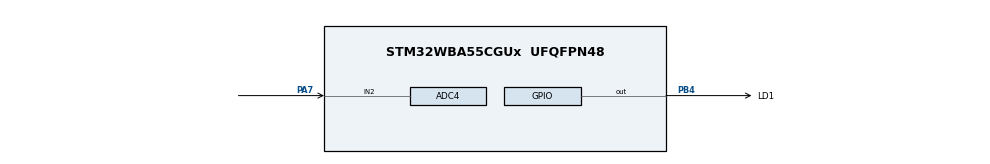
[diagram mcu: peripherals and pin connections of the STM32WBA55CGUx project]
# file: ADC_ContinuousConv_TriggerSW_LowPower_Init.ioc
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ADC4.Channel-0\#ChannelRegularConversion=ADC_CHANNEL_2
ADC4.ClockPrescaler=ADC_CLOCK_ASYNC_DIV4
ADC4.ContinuousConvMode=ENABLE
ADC4.LowPowerAutoPowerOff=DISABLE
ADC4.LowPowerAutoWait=ENABLE
ADC4.NbrOfConversionFlag=1
ADC4.Overrun=ADC_OVR_DATA_OVERWRITTEN
ADC4.Rank-0\#ChannelRegularConversion=1
ADC4.SamplingTime-0\#ChannelRegularConversion=ADC_SAMPLINGTIME_COMMON_1
ADC4.SamplingTimeCommon1=ADC_SAMPLETIME_79CYCLES_5
ADC4.SamplingTimeCommon2=ADC_SAMPLETIME_79CYCLES_5
ADC4.SelectedChannel=ADC_CHANNEL_2
CORTEX_M33_NS.userName=CORTEX_M33
Mcu.Family=STM32WBA
Mcu.Name=STM32WBA55CGUx
Mcu.Package=UFQFPN48
NVIC.PriorityGroup=NVIC_PRIORITYGROUP_4
OSC_IN.Mode=HSE-External-Oscillator
OSC_IN.Signal=RCC_OSC_IN
OSC_OUT.Mode=HSE-External-Oscillator
OSC_OUT.Signal=RCC_OSC_OUT
PA7.Mode=IN2
PA7.Signal=ADC4_IN2
PB4\ (NJTRST).GPIO_Label=LD1
PB4\ (NJTRST).PinState=GPIO_PIN_SET
PB4\ (NJTRST).Signal=GPIO_Output
ProjectManager.HeapSize=0x200
ProjectManager.StackSize=0x400
ProjectManager.TargetToolchain=EWARM V9.20
RCC.ADCCLockSelectionVirtual=RCC_ADCCLKSOURCE_HSI
RCC.ADCFreq_Value=16000000
RCC.AHB5CLKDivider=DIV4
RCC.AHBFreq_Value=100000000
RCC.APB1Freq_Value=100000000
RCC.APB1TimFreq_Value=100000000
RCC.APB2Freq_Value=100000000
RCC.APB2TimFreq_Value=100000000
RCC.CortexFreq_Value=12500000
RCC.HCLKFreq_Value=100000000
RCC.HSE_VALUE=32000000
RCC.HSI_VALUE=16000000
RCC.LSE_VALUE=32768
RCC.LSI1_VALUE=32000
RCC.LSI2_VALUE=32000
RCC.PLLM=4
RCC.PLLN=25
RCC.PLLSourceVirtual=RCC_PLLSOURCE_HSE
RCC.SYSCLKFreq_VALUE=100000000
RCC.SYSCLKSourceVirtual=RCC_SYSCLKSOURCE_PLLCLK
RCC.VCOOutputFreq_Value=200000000
VP_CORTEX_M33_NS_VS_Hclk.Mode=Hclk_Mode
VP_ICACHE_VS_ICACHE.Mode=DirectMappedCache
VP_MEMORYMAP_VS_MEMORYMAP.Mode=CurAppReg
VP_PWR_VS_SECSignals.Mode=Security/Privilege
board=custom

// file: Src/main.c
/* USER CODE BEGIN Header */
/**
  ******************************************************************************
  * @file    Examples_LL/ADC/ADC_ContinuousConv_TriggerSW_LowPower_Init/Src/main.c
  * @author  MCD Application Team
  * @brief   Use ADC to convert a single channel with ADC low power features
  *          auto wait and auto power-off: ADC conversions occurrences are
  *          limited to the minimum necessary to reduce power consumption
  *          and ADC is set automatically in mode disable during idle phase.

  *          These features are intended to be used by applications needing ADC
  *          conversions at few occurrences and without latency constraints.
  *          ADC low power features are used most commonly with programming
  *          model: polling.
  *          This example is based on the STM32WBAxx ADC LL API;
  *          Peripheral initialization done using LL unitary services functions.
  ******************************************************************************
  * @attention
  *
  * Copyright (c) 2023 STMicroelectronics.
  * All rights reserved.
  *
  * This software is licensed under terms that can be found in the LICENSE file
  * in the root directory of this software component.
  * If no LICENSE file comes with this software, it is provided AS-IS.
  *
  ******************************************************************************
  */
/* USER CODE END Header */
#include "main.h"

/* USER CODE BEGIN PD */

/* Definitions of ADC hardware constraints delays */
/* Note: Only ADC IP HW delays are defined in ADC LL driver driver,           */
/*       not timeout values:                                                  */
/*       Timeout values for ADC operations are dependent to device clock      */
/*       configuration (system clock versus ADC clock),                       */
/*       and therefore must be defined in user application.                   */
/*       Refer to @ref ADC_LL_EC_HW_DELAYS for description of ADC timeout     */
/*       values definition.                                                   */

  /* Timeout values for ADC operations. */
  /* (calibration, enable settling time, disable settling time, ...)          */
  /* Values defined to be higher than worst cases: low clock frequency,       */
  /* maximum prescalers.                                                      */
  /* Note: ADC channel configuration ready (ADC_CHANNEL_CONF_RDY_TIMEOUT_MS)  */
  /*       is added in CubeMx code section.                                   */
  /* Unit: ms                                                                 */
  #define ADC_CALIBRATION_TIMEOUT_MS       (   1UL)
  #define ADC_ENABLE_TIMEOUT_MS            (   1UL)
  #define ADC_DISABLE_TIMEOUT_MS           (   1UL)
  #define ADC_STOP_CONVERSION_TIMEOUT_MS   (   1UL)
  #define ADC_CONVERSION_TIMEOUT_MS        (4000UL)

  /* Delay between ADC end of calibration and ADC enable.                     */
  /* Delay estimation in CPU cycles: Case of ADC enable done                  */
  /* immediately after ADC calibration, ADC clock setting slow                */
  /* (LL_ADC_CLOCK_ASYNC_DIV32). Use a higher delay if ratio                  */
  /* (CPU clock / ADC clock) is above 32.                                     */
  #define ADC_DELAY_CALIB_ENABLE_CPU_CYCLES  (LL_ADC_DELAY_CALIB_ENABLE_ADC_CYCLES * 32)

/* Definitions of environment analog values */
  /* Value of analog reference voltage (Vref+), connected to analog voltage   */
  /* supply Vdda (unit: mV).                                                  */
  #define VDDA_APPLI                       (3300UL)

/* Definitions of data related to this example */
  /* Init variable out of expected ADC conversion data range */
  #define VAR_CONVERTED_DATA_INIT_VALUE    (__LL_ADC_DIGITAL_SCALE(LL_ADC_RESOLUTION_12B) + 1)

/* USER CODE END PD */

/* USER CODE BEGIN PV */

/* Variables for ADC conversion data */
__IO uint16_t uhADCxConvertedData = VAR_CONVERTED_DATA_INIT_VALUE; /* ADC group regular conversion data */

/* Variables for ADC conversion data computation to physical values */
uint16_t uhADCxConvertedData_Voltage_mVolt = 0;  /* Value of voltage calculated from ADC conversion data (unit: mV) */

/* USER CODE END PV */

void SystemClock_Config(void);
static void MX_GPIO_Init(void);
static void MX_ADC4_Init(void);
static void MX_ICACHE_Init(void);
/* USER CODE BEGIN PFP */

void ADC_Activate(void);
void ConversionStartPoll_ADC_GrpRegular(void);
void LED_On(void);
void LED_Off(void);
void LED_Toggle(void);

/* USER CODE END PFP */

int main(void)
{

  /* MCU Configuration--------------------------------------------------------*/

  /* Reset of all peripherals, Initializes the Flash interface and the Systick. */

  /* System interrupt init*/
  NVIC_SetPriorityGrouping(NVIC_PRIORITYGROUP_4);

  /* SysTick_IRQn interrupt configuration */
  NVIC_SetPriority(SysTick_IRQn, NVIC_EncodePriority(NVIC_GetPriorityGrouping(),15, 0));

  /* Enable PWR clock interface */

  LL_AHB4_GRP1_EnableClock(LL_AHB4_GRP1_PERIPH_PWR);

  /* Configure the system clock */
  SystemClock_Config();

  /* Initialize all configured peripherals */
  MX_GPIO_Init();
  MX_ADC4_Init();
  MX_ICACHE_Init();
  /* USER CODE BEGIN 2 */

  /* Activate ADC */
  /* Perform ADC activation procedure to make it ready to convert. */
  ADC_Activate();

  /* Perform ADC group regular conversion start, poll for conversion        */
  /* completion.                                                            */
  ConversionStartPoll_ADC_GrpRegular();

  /* USER CODE END 2 */

  /* Infinite loop */
  /* USER CODE BEGIN WHILE */
  while (1)
  {
    /* Note: At this step, ADC is performing ADC conversions automatically,   */
    /*       indefinitely (ADC continuous mode enabled in this example),      */
    /*       but with conversions managed by ADC mode low-power:              */
    /*       After the first trigger (software start in this example),        */
    /*       following conversions are not launched successively              */
    /*       automatically: the ADC performs 1 conversion and remains idle    */
    /*       until conversion data has been processed by user software        */
    /*       (action of retrieve conversion value from ADC data register)     */
    /*       On this STM32 series, on which ADC low power feature             */
    /*       auto power-off is available, ADC is set automatically            */
    /*       in mode disable during idle phase. Then, when ADC conversion     */
    /*       is requested, ADC is set automatically in mode enable.           */

    /* Retrieve ADC conversion data */
    /* Note: As ADC mode low power auto wait is enabled, this action          */
    /*       performs:                                                        */
    /*       - ADC conversion data read                                       */
    /*         Caution: the data read corresponds to the previous ADC         */
    /*         conversion start, independently of delay during which ADC      */
    /*         was idle (low power auto wait). Therefore, ADC conversion      */
    /*         data may be outdated: does not correspond to the current       */
    /*         voltage level on the selected ADC channel.                     */
    /*       - Trig of a new ADC conversion start                             */
    /* Note: In ADC mode low power auto wait, the action triggering a         */
    /*       ADC conversion start is a clear of flag "end of conversion."     */
    /*       - For ADC group regular, ADC conversion data read performs       */
    /*         automatically a clear of flag ADC group regular                */
    /*         end of unitary conversion.                                     */
    /*         Therefore, usage of function "LL_ADC_ClearFlag_EOC()" is not   */
    /*         necessary.                                                     */
    /*       - For ADC group injected (for devices with this features),       */
    /*         data read does not performs a clear of flag ADC group injected */
    /*         end of sequence conversions.                                   */
    /*         Therefore, usage of function "LL_ADC_ClearFlag_JEOS()" is      */
    /*         mandatory.                                                     */

    /* Retrieve ADC conversion data */
    uhADCxConvertedData = LL_ADC_REG_ReadConversionData32(ADC4);

    /* Note: As ADC mode low power auto wait is enabled, after the conversion */
    /*       on going, ADC will remain idle from this step.                   */

    /* Computation of ADC conversions raw data to physical values             */
    /* using helper macro.                                                    */
    uhADCxConvertedData_Voltage_mVolt = __LL_ADC_CALC_DATA_TO_VOLTAGE(VDDA_APPLI, uhADCxConvertedData, LL_ADC_RESOLUTION_12B);

    /* Toggle LED at each ADC conversion data retrieved */
    LED_On();
    LL_mDelay(LED_BLINK_SLOW);
    LED_Off();
    LL_mDelay(LED_BLINK_SLOW);

    /* Note: ADC group regular conversions data are stored into array         */
    /*       "uhADCxConvertedData"                                            */
    /*       (for debug: see variable content into watch window).             */

    /* Note: ADC conversion data are computed to physical values              */
    /*       into array "uhADCxConvertedData_Voltage_mVolt" using             */
    /*       ADC LL driver helper macro "__LL_ADC_CALC_DATA_TO_VOLTAGE()"     */
    /*       (for debug: see variable content with debugger)                  */

    /* USER CODE END WHILE */

  }
}

void SystemClock_Config(void)
{
  LL_FLASH_SetLatency(LL_FLASH_LATENCY_3);
  while(LL_FLASH_GetLatency()!= LL_FLASH_LATENCY_3)
  {
  }

  LL_PWR_SetRegulVoltageScaling(LL_PWR_REGU_VOLTAGE_SCALE1);
  LL_RCC_HSE_Enable();

   /* Wait till HSE is ready */
  while(LL_RCC_HSE_IsReady() != 1)
  {
  }

  LL_RCC_HSI_Enable();

   /* Wait till HSI is ready */
  while(LL_RCC_HSI_IsReady() != 1)
  {
  }

  LL_RCC_HSI_SetCalibTrimming(16);
  LL_RCC_PLL1_ConfigDomain_SYS(LL_RCC_PLL1SOURCE_HSE, 4, 25, 2);
  LL_RCC_PLL1_EnableDomain_PLL1R();
  LL_RCC_PLL1_SetVCOInputRange(LL_RCC_PLLINPUTRANGE_8_16);
  LL_RCC_PLL1_Enable();

   /* Wait till PLL is ready */
  while(LL_RCC_PLL1_IsReady() != 1)
  {
  }

  LL_RCC_SetSysClkSource(LL_RCC_SYS_CLKSOURCE_PLL1R);

   /* Wait till System clock is ready */
  while(LL_RCC_GetSysClkSource() != LL_RCC_SYS_CLKSOURCE_STATUS_PLL1R)
  {
  }

  LL_RCC_SetAHBPrescaler(LL_RCC_SYSCLK_DIV_1);
  LL_RCC_SetAHB5Prescaler(LL_RCC_AHB5_DIV_4);
  LL_RCC_SetAPB1Prescaler(LL_RCC_APB1_DIV_1);
  LL_RCC_SetAPB2Prescaler(LL_RCC_APB2_DIV_1);
  LL_RCC_SetAPB7Prescaler(LL_RCC_APB7_DIV_1);

  LL_Init1msTick(100000000);

  LL_SetSystemCoreClock(100000000);
}

static void MX_ADC4_Init(void)
{

  LL_ADC_InitTypeDef ADC_InitStruct = {0};
  LL_ADC_REG_InitTypeDef ADC_REG_InitStruct = {0};

  LL_GPIO_InitTypeDef GPIO_InitStruct = {0};

  LL_RCC_SetADCClockSource(LL_RCC_ADC_CLKSOURCE_HSI);

  /* Peripheral clock enable */
  LL_AHB4_GRP1_EnableClock(LL_AHB4_GRP1_PERIPH_ADC4);

  LL_AHB2_GRP1_EnableClock(LL_AHB2_GRP1_PERIPH_GPIOA);
  /**ADC4 GPIO Configuration
  PA7   ------> ADC4_IN2
  */
  GPIO_InitStruct.Pin = LL_GPIO_PIN_7;
  GPIO_InitStruct.Mode = LL_GPIO_MODE_ANALOG;
  GPIO_InitStruct.Pull = LL_GPIO_PULL_NO;
  LL_GPIO_Init(GPIOA, &GPIO_InitStruct);

  /** Common config
  */
  LL_ADC_SetTriggerFrequencyMode(ADC4, LL_ADC_TRIGGER_FREQ_LOW);
  ADC_InitStruct.Resolution = LL_ADC_RESOLUTION_12B;
  ADC_InitStruct.DataAlignment = LL_ADC_DATA_ALIGN_RIGHT;
  LL_ADC_Init(ADC4, &ADC_InitStruct);
  LL_ADC_REG_SetSequencerConfigurable(ADC4, LL_ADC_REG_SEQ_CONFIGURABLE);
  ADC_REG_InitStruct.TriggerSource = LL_ADC_REG_TRIG_SOFTWARE;
  ADC_REG_InitStruct.SequencerLength = LL_ADC_REG_SEQ_SCAN_DISABLE;
  ADC_REG_InitStruct.SequencerDiscont = LL_ADC_REG_SEQ_DISCONT_DISABLE;
  ADC_REG_InitStruct.ContinuousMode = LL_ADC_REG_CONV_CONTINUOUS;
  ADC_REG_InitStruct.DMATransfer = LL_ADC_REG_DMA_TRANSFER_LIMITED;
  ADC_REG_InitStruct.Overrun = LL_ADC_REG_OVR_DATA_OVERWRITTEN;
  LL_ADC_REG_Init(ADC4, &ADC_REG_InitStruct);
  LL_ADC_SetLPModeAutoPowerOff(ADC4, DISABLE);
  LL_ADC_SetLPModeAutonomousDPD(ADC4, LL_ADC_LP_AUTONOMOUS_DPD_DISABLE);
  LL_ADC_SetSamplingTimeCommonChannels(ADC4, LL_ADC_SAMPLINGTIME_COMMON_1, LL_ADC_SAMPLINGTIME_79CYCLES_5);
  LL_ADC_SetSamplingTimeCommonChannels(ADC4, LL_ADC_SAMPLINGTIME_COMMON_2, LL_ADC_SAMPLINGTIME_79CYCLES_5);

  /* Enable ADC internal voltage regulator */
  LL_ADC_EnableInternalRegulator(ADC4);
  /* Delay for ADC internal voltage regulator stabilization. */
  /* Compute number of CPU cycles to wait for, from delay in us. */
  /* Note: Variable divided by 2 to compensate partially */
  /* CPU processing cycles (depends on compilation optimization). */
  /* Note: If system core clock frequency is below 200kHz, wait time */
  /* is only a few CPU processing cycles. */
  uint32_t wait_loop_index;
  wait_loop_index = ((LL_ADC_DELAY_INTERNAL_REGUL_STAB_US * (SystemCoreClock / (100000 * 2))) / 10);
  while(wait_loop_index != 0)
  {
    wait_loop_index--;
  }

  /** Configure Regular Channel
  */
  LL_ADC_REG_SetSequencerRanks(ADC4, LL_ADC_REG_RANK_1, LL_ADC_CHANNEL_2);
  LL_ADC_SetChannelSamplingTime(ADC4, LL_ADC_CHANNEL_2, LL_ADC_SAMPLINGTIME_COMMON_1);

}

static void MX_ICACHE_Init(void)
{

  /** Enable instruction cache in 1-way (direct mapped cache)
  */
  LL_ICACHE_SetMode(LL_ICACHE_1WAY);
  LL_ICACHE_Enable();

}

static void MX_GPIO_Init(void)
{
  LL_GPIO_InitTypeDef GPIO_InitStruct = {0};

  /* GPIO Ports Clock Enable */
  LL_AHB2_GRP1_EnableClock(LL_AHB2_GRP1_PERIPH_GPIOA);
  LL_AHB2_GRP1_EnableClock(LL_AHB2_GRP1_PERIPH_GPIOB);

  /**/
  LL_GPIO_SetOutputPin(LD1_GPIO_Port, LD1_Pin);

  /**/
  GPIO_InitStruct.Pin = LD1_Pin;
  GPIO_InitStruct.Mode = LL_GPIO_MODE_OUTPUT;
  GPIO_InitStruct.Speed = LL_GPIO_SPEED_FREQ_LOW;
  GPIO_InitStruct.OutputType = LL_GPIO_OUTPUT_PUSHPULL;
  GPIO_InitStruct.Pull = LL_GPIO_PULL_NO;
  LL_GPIO_Init(LD1_GPIO_Port, &GPIO_InitStruct);

}

/* USER CODE BEGIN 4 */

/**
  * @brief  Perform ADC activation procedure to make it ready to convert
  *         (ADC instance: ADC4).
  * @param  None
  * @retval None
  */
void ADC_Activate(void)
{
  __IO uint32_t wait_loop_index = 0U;
  #if (USE_TIMEOUT == 1)
  uint32_t Timeout = 0U; /* Variable used for timeout management */
  #endif /* USE_TIMEOUT */

  /*## Operation on ADC hierarchical scope: ADC instance #####################*/

  /* Note: Hardware constraint (refer to description of the functions         */
  /*       below):                                                            */
  /*       On this STM32 series, setting of these features is conditioned to  */
  /*       ADC state:                                                         */
  /*       ADC must be disabled.                                              */
  /* Note: In this example, all these checks are not necessary but are        */
  /*       implemented anyway to show the best practice usages                */
  /*       corresponding to reference manual procedure.                       */
  /*       Software can be optimized by removing some of these checks, if     */
  /*       they are not relevant considering previous settings and actions    */
  /*       in user application.                                               */
  if (LL_ADC_IsEnabled(ADC4) == 0)
  {
    /* Enable ADC internal voltage regulator */
    LL_ADC_EnableInternalRegulator(ADC4);

    /* Delay for ADC internal voltage regulator stabilization.                */
    /* Compute number of CPU cycles to wait for, from delay in us.            */
    /* Note: Variable divided by 2 to compensate partially                    */
    /*       CPU processing cycles (depends on compilation optimization).     */
    /* Note: If system core clock frequency is below 200kHz, wait time        */
    /*       is only a few CPU processing cycles.                             */
    wait_loop_index = ((LL_ADC_DELAY_INTERNAL_REGUL_STAB_US * (SystemCoreClock / (100000 * 2))) / 10);
    while(wait_loop_index != 0)
    {
      wait_loop_index--;
    }

    /* Run ADC self calibration */
    LL_ADC_StartCalibration(ADC4);

    /* Poll for ADC effectively calibrated */
    #if (USE_TIMEOUT == 1)
    Timeout = ADC_CALIBRATION_TIMEOUT_MS;
    #endif /* USE_TIMEOUT */

    while (LL_ADC_IsCalibrationOnGoing(ADC4) != 0)
    {
    #if (USE_TIMEOUT == 1)
      /* Check Systick counter flag to decrement the time-out value */
      if (LL_SYSTICK_IsActiveCounterFlag())
      {
        if(Timeout-- == 0)
        {
          /* Error: Time-out */
          Error_Handler();
        }
      }
    #endif /* USE_TIMEOUT */
    }

    /* Delay between ADC end of calibration and ADC enable.                   */
    /* Note: Variable divided by 2 to compensate partially                    */
    /*       CPU processing cycles (depends on compilation optimization).     */
    wait_loop_index = (ADC_DELAY_CALIB_ENABLE_CPU_CYCLES >> 1);
    while(wait_loop_index != 0)
    {
      wait_loop_index--;
    }

    /* Enable ADC */
    LL_ADC_Enable(ADC4);

    /* Poll for ADC ready to convert */
    #if (USE_TIMEOUT == 1)
    Timeout = ADC_ENABLE_TIMEOUT_MS;
    #endif /* USE_TIMEOUT */

    while (LL_ADC_IsActiveFlag_ADRDY(ADC4) == 0)
    {
    #if (USE_TIMEOUT == 1)
      /* Check Systick counter flag to decrement the time-out value */
      if (LL_SYSTICK_IsActiveCounterFlag())
      {
        if(Timeout-- == 0)
        {
          /* Error: Time-out */
          Error_Handler();
        }
      }
    #endif /* USE_TIMEOUT */
    }

    /* Note: ADC flag ADRDY is not cleared here to be able to check ADC       */
    /*       status afterwards.                                               */
    /*       This flag should be cleared at ADC Deactivation, before a new    */
    /*       ADC activation, using function "LL_ADC_ClearFlag_ADRDY()".       */
  }

  /*## Operation on ADC hierarchical scope: ADC group regular ################*/
  /* Note: No operation on ADC group regular performed here.                  */
  /*       ADC group regular conversions to be performed after this function  */
  /*       using function:                                                    */
  /*       "LL_ADC_REG_StartConversion();"                                    */

  /*## Operation on ADC hierarchical scope: ADC group injected ###############*/
  /* Note: Feature not available on this STM32 series */

}

/**
  * @brief  Perform ADC group regular conversion start, poll for conversion
  *         completion.
  *         (ADC instance: ADC4).
  * @note   This function does not perform ADC group regular conversion stop:
  *         intended to be used with ADC in single mode, trigger SW start
  *         (only 1 ADC conversion done at each trigger, no conversion stop
  *         needed).
  *         In case of continuous mode or conversion trigger set to
  *         external trigger, ADC group regular conversion stop must be added
  *         after polling for conversion data.
  * @param  None
  * @retval None
  */
void ConversionStartPoll_ADC_GrpRegular(void)
{
  #if (USE_TIMEOUT == 1)
  uint32_t Timeout = 0U; /* Variable used for timeout management */
  #endif /* USE_TIMEOUT */

  /* Start ADC group regular conversion */
  /* Note: Hardware constraint (refer to description of the function          */
  /*       below):                                                            */
  /*       On this STM32 series, setting of this feature is conditioned to    */
  /*       ADC state:                                                         */
  /*       ADC must be enabled without conversion on going on group regular,  */
  /*       without ADC disable command on going.                              */
  /* Note: In this example, all these checks are not necessary but are        */
  /*       implemented anyway to show the best practice usages                */
  /*       corresponding to reference manual procedure.                       */
  /*       Software can be optimized by removing some of these checks, if     */
  /*       they are not relevant considering previous settings and actions    */
  /*       in user application.                                               */
  if ((LL_ADC_IsEnabled(ADC4) == 1)               &&
      (LL_ADC_IsDisableOngoing(ADC4) == 0)        &&
      (LL_ADC_REG_IsConversionOngoing(ADC4) == 0)   )
  {
    LL_ADC_REG_StartConversion(ADC4);
  }
  else
  {
    /* Error: ADC conversion start could not be performed */
    Error_Handler();
  }

  #if (USE_TIMEOUT == 1)
  Timeout = ADC_UNITARY_CONVERSION_TIMEOUT_MS;
  #endif /* USE_TIMEOUT */

  while (LL_ADC_IsActiveFlag_EOC(ADC4) == 0)
  {
  #if (USE_TIMEOUT == 1)
    /* Check Systick counter flag to decrement the time-out value */
    if (LL_SYSTICK_IsActiveCounterFlag())
    {
      if(Timeout-- == 0)
      {
        Error_Handler();
      }
    }
  #endif /* USE_TIMEOUT */
  }

  /* Clear flag ADC group regular end of unitary conversion */
  /* Note: This action is not needed here, because flag ADC group regular   */
  /*       end of unitary conversion is cleared automatically when          */
  /*       software reads conversion data from ADC data register.           */
  /*       Nevertheless, this action is done anyway to show how to clear    */
  /*       this flag, needed if conversion data is not always read          */
  /*       or if group injected end of unitary conversion is used (for      */
  /*       devices with group injected available).                          */
  LL_ADC_ClearFlag_EOC(ADC4);

}

/**
  * @brief  Turn-on LD1.
  * @param  None
  * @retval None
  */
void LED_On(void)
{
  /* Turn LED on */
  LL_GPIO_SetOutputPin(LD1_GPIO_Port, LD1_Pin);
}

/**
  * @brief  Turn-off LD1.
  * @param  None
  * @retval None
  */
void LED_Off(void)
{
  /* Turn LED off */
  LL_GPIO_ResetOutputPin(LD1_GPIO_Port, LD1_Pin);
}

/**
  * @brief  Toggle LD1.
  * @param  None
  * @retval None
  */
void LED_Toggle(void)
{
  /* Turn LED off */
  LL_GPIO_TogglePin(LD1_GPIO_Port, LD1_Pin);
}

/* USER CODE END 4 */

void Error_Handler(void)
{
  /* USER CODE BEGIN Error_Handler_Debug */
  /* User can add his own implementation to report the HAL error return state */

  /* Turn on LED and remain in infinite loop */
  while (1)
  {
    LED_On();
  }
  /* USER CODE END Error_Handler_Debug */
}
